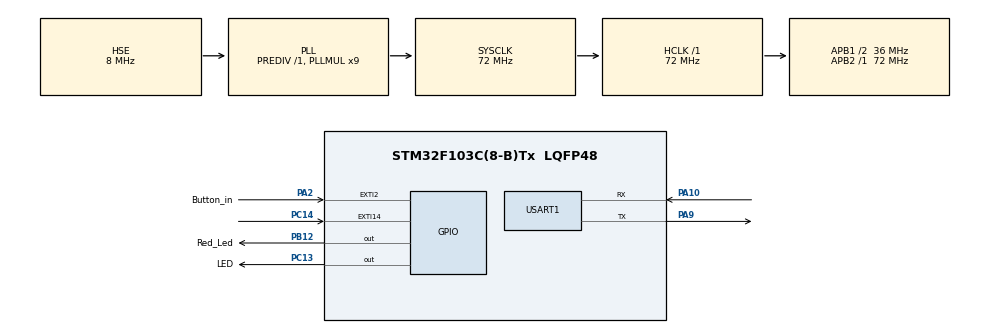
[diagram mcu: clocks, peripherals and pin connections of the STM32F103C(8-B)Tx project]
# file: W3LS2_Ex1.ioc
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Mcu.Family=STM32F1
Mcu.Name=STM32F103C(8-B)Tx
Mcu.Package=LQFP48
NVIC.EXTI15_10_IRQn=true\:1\:0\:true\:false\:true\:true\:true
NVIC.EXTI2_IRQn=true\:1\:0\:true\:false\:true\:true\:true
NVIC.PriorityGroup=NVIC_PRIORITYGROUP_4
PA10.Mode=Asynchronous
PA10.Signal=USART1_RX
PA13.Mode=Trace_Asynchronous_SW
PA13.Signal=SYS_JTMS-SWDIO
PA14.Mode=Trace_Asynchronous_SW
PA14.Signal=SYS_JTCK-SWCLK
PA2.GPIO_Label=Button_in
PA2.Signal=GPXTI2
PA9.Mode=Asynchronous
PA9.Signal=USART1_TX
PB12.GPIO_Label=Red_Led
PB12.Signal=GPIO_Output
PB3.Mode=Trace_Asynchronous_SW
PB3.Signal=SYS_JTDO-TRACESWO
PC13-TAMPER-RTC.GPIO_Label=LED
PC13-TAMPER-RTC.Signal=GPIO_Output
PC14-OSC32_IN.Signal=GPXTI14
PD0-OSC_IN.Mode=HSE-External-Oscillator
PD0-OSC_IN.Signal=RCC_OSC_IN
PD1-OSC_OUT.Mode=HSE-External-Oscillator
PD1-OSC_OUT.Signal=RCC_OSC_OUT
ProjectManager.HeapSize=0x200
ProjectManager.StackSize=0x400
ProjectManager.TargetToolchain=STM32CubeIDE
RCC.AHBFreq_Value=72000000
RCC.APB1CLKDivider=RCC_HCLK_DIV2
RCC.APB1Freq_Value=36000000
RCC.APB1TimFreq_Value=72000000
RCC.APB2Freq_Value=72000000
RCC.APB2TimFreq_Value=72000000
RCC.HCLKFreq_Value=72000000
RCC.PLLMUL=RCC_PLL_MUL9
RCC.PLLSourceVirtual=RCC_PLLSOURCE_HSE
RCC.SYSCLKFreq_VALUE=72000000
RCC.SYSCLKSource=RCC_SYSCLKSOURCE_PLLCLK
RCC.USBFreq_Value=72000000
USART1.VirtualMode=VM_ASYNC
board=custom

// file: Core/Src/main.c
/* USER CODE BEGIN Header */
/**
  ******************************************************************************
  * @file           : main.c
  * @brief          : Main program body
  ******************************************************************************
  * @attention
  *
  * <h2><center>&copy; Copyright (c) 2021 STMicroelectronics.
  * All rights reserved.</center></h2>
  *
  * This software component is licensed by ST under BSD 3-Clause license,
  * the "License"; You may not use this file except in compliance with the
  * License. You may obtain a copy of the License at:
  *                        opensource.org/licenses/BSD-3-Clause
  *
  ******************************************************************************
  */
/* USER CODE END Header */
#include "main.h"

UART_HandleTypeDef huart1;
uint8_t I=0;

void SystemClock_Config(void);
static void MX_GPIO_Init(void);
static void MX_USART1_UART_Init(void);

/* USER CODE BEGIN 0 */
void HAL_GPIO_EXTI_Callback(uint16_t GPIO_Pin){
	//int count=0;

	if (GPIO_Pin == Button_in_Pin)
	{
		for (int i=0; i<=20; i++){
		HAL_GPIO_TogglePin(LED_GPIO_Port, LED_Pin);
		HAL_Delay(50);
		HAL_GPIO_TogglePin(LED_GPIO_Port, LED_Pin);
		HAL_Delay(50);
		}

	}

}
/* USER CODE END 0 */

int main(void)
{
  /* USER CODE BEGIN 1 */
	HAL_NVIC_EnableIRQ(EXTI2_IRQn);

  /* USER CODE END 1 */

  /* MCU Configuration--------------------------------------------------------*/

  /* Reset of all peripherals, Initializes the Flash interface and the Systick. */
  HAL_Init();

  /* Configure the system clock */
  SystemClock_Config();

  /* Initialize all configured peripherals */
  MX_GPIO_Init();
  MX_USART1_UART_Init();

  /* Infinite loop */
  while (1)
  {

    /* USER CODE BEGIN 3 */
	  HAL_GPIO_TogglePin(Red_Led_GPIO_Port, Red_Led_Pin);
	  HAL_Delay(500);
	  I++;

  }
  /* USER CODE END 3 */
}

void SystemClock_Config(void)
{
  RCC_OscInitTypeDef RCC_OscInitStruct = {0};
  RCC_ClkInitTypeDef RCC_ClkInitStruct = {0};

  /** Initializes the RCC Oscillators according to the specified parameters
  * in the RCC_OscInitTypeDef structure.
  */
  RCC_OscInitStruct.OscillatorType = RCC_OSCILLATORTYPE_HSE;
  RCC_OscInitStruct.HSEState = RCC_HSE_ON;
  RCC_OscInitStruct.HSEPredivValue = RCC_HSE_PREDIV_DIV1;
  RCC_OscInitStruct.HSIState = RCC_HSI_ON;
  RCC_OscInitStruct.PLL.PLLState = RCC_PLL_ON;
  RCC_OscInitStruct.PLL.PLLSource = RCC_PLLSOURCE_HSE;
  RCC_OscInitStruct.PLL.PLLMUL = RCC_PLL_MUL9;
  if (HAL_RCC_OscConfig(&RCC_OscInitStruct) != HAL_OK)
  {
    Error_Handler();
  }
  /** Initializes the CPU, AHB and APB buses clocks
  */
  RCC_ClkInitStruct.ClockType = RCC_CLOCKTYPE_HCLK|RCC_CLOCKTYPE_SYSCLK
                              |RCC_CLOCKTYPE_PCLK1|RCC_CLOCKTYPE_PCLK2;
  RCC_ClkInitStruct.SYSCLKSource = RCC_SYSCLKSOURCE_PLLCLK;
  RCC_ClkInitStruct.AHBCLKDivider = RCC_SYSCLK_DIV1;
  RCC_ClkInitStruct.APB1CLKDivider = RCC_HCLK_DIV2;
  RCC_ClkInitStruct.APB2CLKDivider = RCC_HCLK_DIV1;

  if (HAL_RCC_ClockConfig(&RCC_ClkInitStruct, FLASH_LATENCY_2) != HAL_OK)
  {
    Error_Handler();
  }
}

static void MX_USART1_UART_Init(void)
{

  huart1.Instance = USART1;
  huart1.Init.BaudRate = 115200;
  huart1.Init.WordLength = UART_WORDLENGTH_8B;
  huart1.Init.StopBits = UART_STOPBITS_1;
  huart1.Init.Parity = UART_PARITY_NONE;
  huart1.Init.Mode = UART_MODE_TX_RX;
  huart1.Init.HwFlowCtl = UART_HWCONTROL_NONE;
  huart1.Init.OverSampling = UART_OVERSAMPLING_16;
  if (HAL_UART_Init(&huart1) != HAL_OK)
  {
    Error_Handler();
  }

}

static void MX_GPIO_Init(void)
{
  GPIO_InitTypeDef GPIO_InitStruct = {0};

  /* GPIO Ports Clock Enable */
  __HAL_RCC_GPIOC_CLK_ENABLE();
  __HAL_RCC_GPIOD_CLK_ENABLE();
  __HAL_RCC_GPIOA_CLK_ENABLE();
  __HAL_RCC_GPIOB_CLK_ENABLE();

  /*Configure GPIO pin Output Level */
  HAL_GPIO_WritePin(LED_GPIO_Port, LED_Pin, GPIO_PIN_RESET);

  /*Configure GPIO pin Output Level */
  HAL_GPIO_WritePin(Red_Led_GPIO_Port, Red_Led_Pin, GPIO_PIN_RESET);

  /*Configure GPIO pin : LED_Pin */
  GPIO_InitStruct.Pin = LED_Pin;
  GPIO_InitStruct.Mode = GPIO_MODE_OUTPUT_PP;
  GPIO_InitStruct.Pull = GPIO_NOPULL;
  GPIO_InitStruct.Speed = GPIO_SPEED_FREQ_LOW;
  HAL_GPIO_Init(LED_GPIO_Port, &GPIO_InitStruct);

  /*Configure GPIO pin : PC14 */
  GPIO_InitStruct.Pin = GPIO_PIN_14;
  GPIO_InitStruct.Mode = GPIO_MODE_IT_RISING;
  GPIO_InitStruct.Pull = GPIO_NOPULL;
  HAL_GPIO_Init(GPIOC, &GPIO_InitStruct);

  /*Configure GPIO pin : Button_in_Pin */
  GPIO_InitStruct.Pin = Button_in_Pin;
  GPIO_InitStruct.Mode = GPIO_MODE_IT_RISING;
  GPIO_InitStruct.Pull = GPIO_NOPULL;
  HAL_GPIO_Init(Button_in_GPIO_Port, &GPIO_InitStruct);

  /*Configure GPIO pin : Red_Led_Pin */
  GPIO_InitStruct.Pin = Red_Led_Pin;
  GPIO_InitStruct.Mode = GPIO_MODE_OUTPUT_PP;
  GPIO_InitStruct.Pull = GPIO_NOPULL;
  GPIO_InitStruct.Speed = GPIO_SPEED_FREQ_LOW;
  HAL_GPIO_Init(Red_Led_GPIO_Port, &GPIO_InitStruct);

  /* EXTI interrupt init*/
  HAL_NVIC_SetPriority(EXTI2_IRQn, 1, 0);
  HAL_NVIC_EnableIRQ(EXTI2_IRQn);

  HAL_NVIC_SetPriority(EXTI15_10_IRQn, 1, 0);
  HAL_NVIC_EnableIRQ(EXTI15_10_IRQn);

}

void Error_Handler(void)
{
}

/************************ (C) COPYRIGHT STMicroelectronics *****END OF FILE****/
